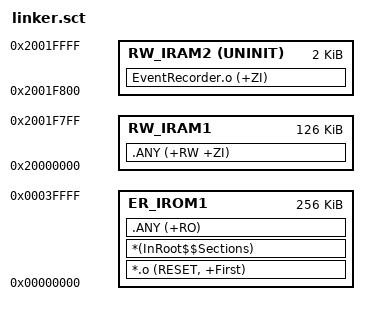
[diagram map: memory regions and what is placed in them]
; Copyright (c) 2022 Arm Limited and Contributors. All rights reserved.
; SPDX-License-Identifier: Apache-2.0

LR_IROM1 0x00000000 0x00040000  {    ; load region size_region
  ER_IROM1 0x00000000 0x00040000  {  ; load address = execution address
   *.o (RESET, +First)
   *(InRoot$$Sections)
   .ANY (+RO)
  }
  RW_IRAM1 0x20000000 0x0001F800  {  ; RW data
   .ANY (+RW +ZI)
  }
  RW_IRAM2 0x2001F800 UNINIT 0x00000800  {
    EventRecorder.o (+ZI)
  }
}
